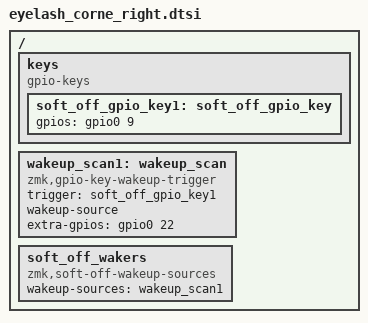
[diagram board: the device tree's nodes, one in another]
/*
*
* Copyright (c) 2024 The ZMK Contributors
* SPDX-License-Identifier: MIT
*
*/

/ {
    keys {
        compatible = "gpio-keys";
        soft_off_gpio_key1: soft_off_gpio_key {
            gpios = <&gpio0  9 (GPIO_ACTIVE_HIGH | GPIO_PULL_DOWN)>;
        };
    };

    wakeup_scan1: wakeup_scan {
        compatible = "zmk,gpio-key-wakeup-trigger";
        trigger = <&soft_off_gpio_key1>;
        wakeup-source;
        extra-gpios = <&gpio0 22 GPIO_ACTIVE_HIGH>;
    };

    soft_off_wakers {
        compatible = "zmk,soft-off-wakeup-sources";
        wakeup-sources = <&wakeup_scan1>;
    };
};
